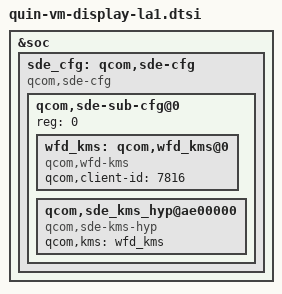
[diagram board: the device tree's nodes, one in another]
&soc {
	sde_cfg: qcom,sde-cfg {
		compatible = "qcom,sde-cfg";

		qcom,sde-sub-cfg@0 {
			reg = <0>;
			wfd_kms: qcom,wfd_kms@0 {
				compatible = "qcom,wfd-kms";
				qcom,client-id = "7816";
			};

			qcom,sde_kms_hyp@ae00000 {
				compatible = "qcom,sde-kms-hyp";
				qcom,kms = <&wfd_kms>;
			};
		};
	};
};
